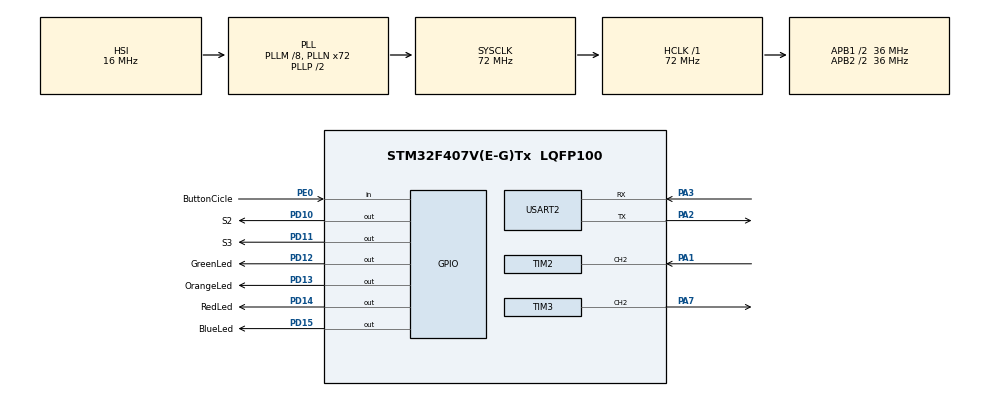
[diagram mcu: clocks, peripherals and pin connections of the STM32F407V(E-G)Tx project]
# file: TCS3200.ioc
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Mcu.Family=STM32F4
Mcu.Name=STM32F407V(E-G)Tx
Mcu.Package=LQFP100
NVIC.PriorityGroup=NVIC_PRIORITYGROUP_0
NVIC.TIM2_IRQn=true\:0\:0\:false\:false\:true\:true\:true
NVIC.TIM3_IRQn=true\:0\:0\:false\:false\:true\:true\:true
PA1.Signal=S_TIM2_CH2
PA2.Mode=Asynchronous
PA2.Signal=USART2_TX
PA3.Mode=Asynchronous
PA3.Signal=USART2_RX
PA7.Signal=S_TIM3_CH2
PD10.GPIO_Label=S2
PD10.Signal=GPIO_Output
PD11.GPIO_Label=S3
PD11.Signal=GPIO_Output
PD12.GPIO_Label=GreenLed
PD12.Signal=GPIO_Output
PD13.GPIO_Label=OrangeLed
PD13.Signal=GPIO_Output
PD14.GPIO_Label=RedLed
PD14.Signal=GPIO_Output
PD15.GPIO_Label=BlueLed
PD15.Signal=GPIO_Output
PE0.GPIO_Label=ButtonCicle
PE0.GPIO_PuPd=GPIO_PULLUP
PE0.Signal=GPIO_Input
ProjectManager.HeapSize=0x200
ProjectManager.StackSize=0x400
ProjectManager.TargetToolchain=MDK-ARM V5.27
RCC.48MHZClocksFreq_Value=20571428.57142857
RCC.AHBFreq_Value=72000000
RCC.APB1CLKDivider=RCC_HCLK_DIV2
RCC.APB1Freq_Value=36000000
RCC.APB1TimFreq_Value=72000000
RCC.APB2CLKDivider=RCC_HCLK_DIV2
RCC.APB2Freq_Value=36000000
RCC.APB2TimFreq_Value=72000000
RCC.CortexFreq_Value=72000000
RCC.HCLKFreq_Value=72000000
RCC.HSE_VALUE=8000000
RCC.HSI_VALUE=16000000
RCC.PLLM=8
RCC.PLLN=72
RCC.PLLQ=7
RCC.SYSCLKFreq_VALUE=72000000
RCC.SYSCLKSource=RCC_SYSCLKSOURCE_PLLCLK
RCC.VCOOutputFreq_Value=144000000
SH.S_TIM2_CH2.0=TIM2_CH2,Input_Capture2_from_TI2
SH.S_TIM3_CH2.0=TIM3_CH2,PWM Generation2 CH2
TIM2.Channel-Input_Capture2_from_TI2=TIM_CHANNEL_2
TIM2.Period=0xFFFF-1
TIM2.Prescaler=72-1
TIM3.Channel-PWM\ Generation2\ CH2=TIM_CHANNEL_2
TIM3.Period=0xFFFF-1
TIM3.Prescaler=72-1
USART2.VirtualMode=VM_ASYNC
board=STM32F407G-DISC1

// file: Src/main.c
/* USER CODE BEGIN Header */
/**
  ******************************************************************************
  * @file           : main.c
  * @brief          : Main program body
  ******************************************************************************
  * @attention
  *
  * <h2><center>&copy; Copyright (c) 2020 STMicroelectronics.
  * All rights reserved.</center></h2>
  *
  * This software component is licensed by ST under BSD 3-Clause license,
  * the "License"; You may not use this file except in compliance with the
  * License. You may obtain a copy of the License at:
  *                        opensource.org/licenses/BSD-3-Clause
  *
  ******************************************************************************
  */
/* USER CODE END Header */

#include "main.h"

/* USER CODE BEGIN Includes */
#include "tcs3200.h"
#include "servos_buttons.h"
/* USER CODE END Includes */

TIM_HandleTypeDef htim2;
TIM_HandleTypeDef htim3;

UART_HandleTypeDef huart2;

void SystemClock_Config(void);
static void MX_GPIO_Init(void);
static void MX_TIM2_Init(void);
static void MX_TIM3_Init(void);
static void MX_USART2_UART_Init(void);

int main(void)
{

  /* MCU Configuration--------------------------------------------------------*/

  /* Reset of all peripherals, Initializes the Flash interface and the Systick. */
  HAL_Init();

  /* Configure the system clock */
  SystemClock_Config();

  /* Initialize all configured peripherals */
  MX_GPIO_Init();
  MX_TIM2_Init();
  MX_TIM3_Init();
  MX_USART2_UART_Init();

  /* Infinite loop */
  while (1)
  {

  }
}

void SystemClock_Config(void)
{
  RCC_OscInitTypeDef RCC_OscInitStruct = {0};
  RCC_ClkInitTypeDef RCC_ClkInitStruct = {0};

  /** Configure the main internal regulator output voltage
  */
  __HAL_RCC_PWR_CLK_ENABLE();
  __HAL_PWR_VOLTAGESCALING_CONFIG(PWR_REGULATOR_VOLTAGE_SCALE1);
  /** Initializes the CPU, AHB and APB busses clocks
  */
  RCC_OscInitStruct.OscillatorType = RCC_OSCILLATORTYPE_HSI;
  RCC_OscInitStruct.HSIState = RCC_HSI_ON;
  RCC_OscInitStruct.HSICalibrationValue = RCC_HSICALIBRATION_DEFAULT;
  RCC_OscInitStruct.PLL.PLLState = RCC_PLL_ON;
  RCC_OscInitStruct.PLL.PLLSource = RCC_PLLSOURCE_HSI;
  RCC_OscInitStruct.PLL.PLLM = 8;
  RCC_OscInitStruct.PLL.PLLN = 72;
  RCC_OscInitStruct.PLL.PLLP = RCC_PLLP_DIV2;
  RCC_OscInitStruct.PLL.PLLQ = 7;
  if (HAL_RCC_OscConfig(&RCC_OscInitStruct) != HAL_OK)
  {
    Error_Handler();
  }
  /** Initializes the CPU, AHB and APB busses clocks
  */
  RCC_ClkInitStruct.ClockType = RCC_CLOCKTYPE_HCLK|RCC_CLOCKTYPE_SYSCLK
                              |RCC_CLOCKTYPE_PCLK1|RCC_CLOCKTYPE_PCLK2;
  RCC_ClkInitStruct.SYSCLKSource = RCC_SYSCLKSOURCE_PLLCLK;
  RCC_ClkInitStruct.AHBCLKDivider = RCC_SYSCLK_DIV1;
  RCC_ClkInitStruct.APB1CLKDivider = RCC_HCLK_DIV2;
  RCC_ClkInitStruct.APB2CLKDivider = RCC_HCLK_DIV2;

  if (HAL_RCC_ClockConfig(&RCC_ClkInitStruct, FLASH_LATENCY_2) != HAL_OK)
  {
    Error_Handler();
  }
}

static void MX_TIM2_Init(void)
{

  TIM_MasterConfigTypeDef sMasterConfig = {0};
  TIM_IC_InitTypeDef sConfigIC = {0};

  htim2.Instance = TIM2;
  htim2.Init.Prescaler = 72-1;
  htim2.Init.CounterMode = TIM_COUNTERMODE_UP;
  htim2.Init.Period = 0xFFFF-1;
  htim2.Init.ClockDivision = TIM_CLOCKDIVISION_DIV1;
  htim2.Init.AutoReloadPreload = TIM_AUTORELOAD_PRELOAD_DISABLE;
  if (HAL_TIM_IC_Init(&htim2) != HAL_OK)
  {
    Error_Handler();
  }
  sMasterConfig.MasterOutputTrigger = TIM_TRGO_RESET;
  sMasterConfig.MasterSlaveMode = TIM_MASTERSLAVEMODE_DISABLE;
  if (HAL_TIMEx_MasterConfigSynchronization(&htim2, &sMasterConfig) != HAL_OK)
  {
    Error_Handler();
  }
  sConfigIC.ICPolarity = TIM_INPUTCHANNELPOLARITY_RISING;
  sConfigIC.ICSelection = TIM_ICSELECTION_DIRECTTI;
  sConfigIC.ICPrescaler = TIM_ICPSC_DIV1;
  sConfigIC.ICFilter = 0;
  if (HAL_TIM_IC_ConfigChannel(&htim2, &sConfigIC, TIM_CHANNEL_2) != HAL_OK)
  {
    Error_Handler();
  }

}

static void MX_TIM3_Init(void)
{

  TIM_MasterConfigTypeDef sMasterConfig = {0};
  TIM_OC_InitTypeDef sConfigOC = {0};

  htim3.Instance = TIM3;
  htim3.Init.Prescaler = 72-1;
  htim3.Init.CounterMode = TIM_COUNTERMODE_UP;
  htim3.Init.Period = 0xFFFF-1;
  htim3.Init.ClockDivision = TIM_CLOCKDIVISION_DIV1;
  htim3.Init.AutoReloadPreload = TIM_AUTORELOAD_PRELOAD_DISABLE;
  if (HAL_TIM_PWM_Init(&htim3) != HAL_OK)
  {
    Error_Handler();
  }
  sMasterConfig.MasterOutputTrigger = TIM_TRGO_RESET;
  sMasterConfig.MasterSlaveMode = TIM_MASTERSLAVEMODE_DISABLE;
  if (HAL_TIMEx_MasterConfigSynchronization(&htim3, &sMasterConfig) != HAL_OK)
  {
    Error_Handler();
  }
  sConfigOC.OCMode = TIM_OCMODE_PWM1;
  sConfigOC.Pulse = 0;
  sConfigOC.OCPolarity = TIM_OCPOLARITY_HIGH;
  sConfigOC.OCFastMode = TIM_OCFAST_DISABLE;
  if (HAL_TIM_PWM_ConfigChannel(&htim3, &sConfigOC, TIM_CHANNEL_2) != HAL_OK)
  {
    Error_Handler();
  }
  HAL_TIM_MspPostInit(&htim3);

}

static void MX_USART2_UART_Init(void)
{

  huart2.Instance = USART2;
  huart2.Init.BaudRate = 115200;
  huart2.Init.WordLength = UART_WORDLENGTH_8B;
  huart2.Init.StopBits = UART_STOPBITS_1;
  huart2.Init.Parity = UART_PARITY_NONE;
  huart2.Init.Mode = UART_MODE_TX_RX;
  huart2.Init.HwFlowCtl = UART_HWCONTROL_NONE;
  huart2.Init.OverSampling = UART_OVERSAMPLING_16;
  if (HAL_UART_Init(&huart2) != HAL_OK)
  {
    Error_Handler();
  }

}

static void MX_GPIO_Init(void)
{
  GPIO_InitTypeDef GPIO_InitStruct = {0};

  /* GPIO Ports Clock Enable */
  __HAL_RCC_GPIOA_CLK_ENABLE();
  __HAL_RCC_GPIOD_CLK_ENABLE();
  __HAL_RCC_GPIOE_CLK_ENABLE();

  /*Configure GPIO pin Output Level */
  HAL_GPIO_WritePin(GPIOD, S2_Pin|S3_Pin|GreenLed_Pin|OrangeLed_Pin
                          |RedLed_Pin|BlueLed_Pin, GPIO_PIN_RESET);

  /*Configure GPIO pins : S2_Pin S3_Pin GreenLed_Pin OrangeLed_Pin
                           RedLed_Pin BlueLed_Pin */
  GPIO_InitStruct.Pin = S2_Pin|S3_Pin|GreenLed_Pin|OrangeLed_Pin
                          |RedLed_Pin|BlueLed_Pin;
  GPIO_InitStruct.Mode = GPIO_MODE_OUTPUT_PP;
  GPIO_InitStruct.Pull = GPIO_NOPULL;
  GPIO_InitStruct.Speed = GPIO_SPEED_FREQ_LOW;
  HAL_GPIO_Init(GPIOD, &GPIO_InitStruct);

  /*Configure GPIO pin : ButtonCicle_Pin */
  GPIO_InitStruct.Pin = ButtonCicle_Pin;
  GPIO_InitStruct.Mode = GPIO_MODE_INPUT;
  GPIO_InitStruct.Pull = GPIO_PULLUP;
  HAL_GPIO_Init(ButtonCicle_GPIO_Port, &GPIO_InitStruct);

}

void Error_Handler(void)
{
}

/************************ (C) COPYRIGHT STMicroelectronics *****END OF FILE****/
